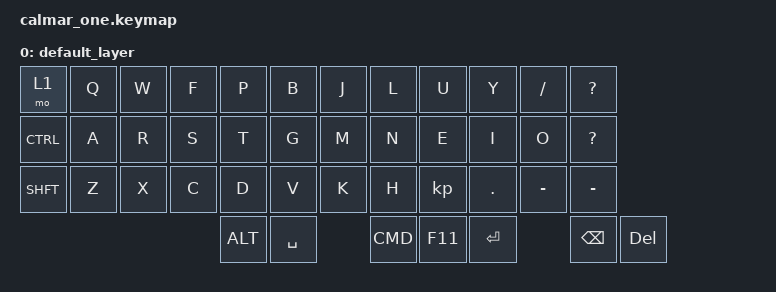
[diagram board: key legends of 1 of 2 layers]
#include <behaviors.dtsi>
#include <dt-bindings/zmk/keys.h>
#include <dt-bindings/zmk/bt.h>

/ {  
    keymap {
        compatible = "zmk,keymap";

        default_layer {
            bindings = <
                &mo 1     &kp Q   &kp W   &kp F   &kp P  &kp B  &kp J   &kp L   &kp U   &kp Y   &kp /   &kp ?
                &kp CTRL  &kp A   &kp R   &kp S   &kp T  &kp G  &kp M   &kp N   &kp E   &kp I   &kp O   &kp ?
                &kp SHFT  &kp Z   &kp X   &kp C   &kp D  &kp V  &kp K   &kp H   &kp ,   &kp .   &kp -   &kp -
                                                  &kp ALT   &kp SPACE   &kp CMD   &kp F11   &kp ENTER   &kp BSPC  &kp DEL     
            >;
        }; 
        
        bt_layer {
            bindings = <
                &none            &none            &bootloader
                &none            &none            &bt BT_CLR
                &bt BT_SEL 0     &bt BT_SEL 1     &bt BT_SEL 2
            >;
        };
    };
};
